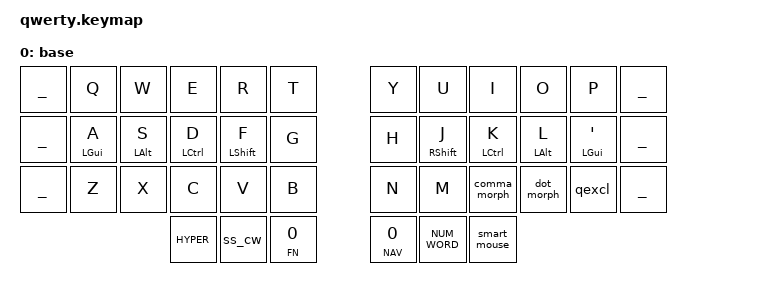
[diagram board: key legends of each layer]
ZMK_LAYER(base, // 0
//╭─────────────┬─────────────┬─────────────┬─────────────┬─────────────┬─────────────╮ ╭─────────────┬─────────────┬─────────────┬─────────────┬─────────────┬─────────────╮
    ___           &kp Q         &kp W         &kp E         &kp R         &kp T           &kp Y         &kp U         &kp I         &kp O         &kp P         ___
//├─────────────┼─────────────┼─────────────┼─────────────┼─────────────┼─────────────┤ ├─────────────┼─────────────┼─────────────┼─────────────┼─────────────┴─────────────┤
    ___           &hml LGUI A   &hml LALT S   &hml LCTRL D  &hml LSHFT F  &kp G           &kp H         &hmr RSHFT J  &hmr LCTRL K  &hmr LALT L  &hmr LGUI SQT  ___
//├─────────────┼─────────────┼─────────────┼─────────────┼─────────────┼─────────────┤ ├─────────────┼─────────────┼─────────────┼─────────────┼─────────────┴─────────────┤
    ___           &kp Z         &kp X         &kp C         &kp V         &kp B           &kp N         &kp M         &comma_morph  &dot_morph    &qexcl        ___
//╰─────────────┴─────────────┴─────────────┼─────────────┼─────────────┼─────────────┤ ├─────────────┼─────────────┼─────────────┼─────────────┴─────────────┴─────────────╯
                                              HYPER         &ss_cw        &lt_bspc FN 0   &lt_spc NAV 0 NUM_WORD      &smart_mouse
//                                          ╰─────────────┴─────────────┴─────────────╯ ╰─────────────┴─────────────┴─────────────╯
)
